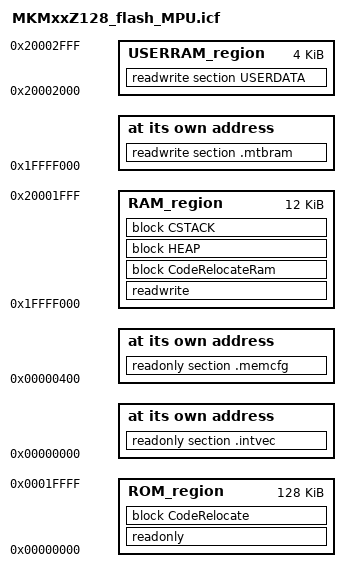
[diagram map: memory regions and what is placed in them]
/*###ICF### Section handled by ICF editor, don't touch! ****/
/*-Editor annotation file-*/
/* IcfEditorFile="$TOOLKIT_DIR$\config\ide\IcfEditor\cortex_v1_0.xml" */
/*-Specials-*/
define symbol __ICFEDIT_intvec_start__     = 0x00000000;
/*-Memory Regions-*/
define symbol __ICFEDIT_region_ROM_start__ = 0x00000000;
define symbol __ICFEDIT_region_ROM_end__   = 0x0001ffff;
define symbol __ICFEDIT_region_RAM_start__ = 0x1ffff000;
define symbol __ICFEDIT_region_RAM_end__   = 0x20001fff;
define symbol __ICFEDIT_region_USERRAM_start__ = 0x20002000;
define symbol __ICFEDIT_region_USERRAM_end__   = 0x20002fff;
/*-Sizes-*/
define symbol __ICFEDIT_size_cstack__ = 0x400;
define symbol __ICFEDIT_size_heap__   = 0x800;
/**** End of ICF editor section. ###ICF###*/

define symbol __memcfg_start__        = 0x00000400;
define symbol __mtbram_start__        = 0x1ffff000;

/* Export of symbol */
export symbol __ICFEDIT_region_ROM_start__;
export symbol __ICFEDIT_region_ROM_end__;
export symbol __ICFEDIT_region_RAM_start__;
export symbol __ICFEDIT_region_RAM_end__;
export symbol __ICFEDIT_region_USERRAM_start__;
export symbol __ICFEDIT_region_USERRAM_end__;

define memory mem with size = 4G;
define region ROM_region = mem:[from __ICFEDIT_region_ROM_start__ to __ICFEDIT_region_ROM_end__];
define region RAM_region = mem:[from __ICFEDIT_region_RAM_start__ to __ICFEDIT_region_RAM_end__];
define region USERRAM_region = mem:[from __ICFEDIT_region_USERRAM_start__ to __ICFEDIT_region_USERRAM_end__];

define block CSTACK    with alignment = 8, size = __ICFEDIT_size_cstack__   { };
define block HEAP      with alignment = 8, size = __ICFEDIT_size_heap__     { };

initialize manually { readwrite };
initialize manually { section .data};
initialize manually { section .textrw };
initialize manually { section USERDATA };
do not initialize   { zeroinit };

define block CodeRelocate { section .textrw_init };
define block CodeRelocateRam { section .textrw };

place at address mem:__ICFEDIT_intvec_start__ { readonly  section .intvec };
place at address mem:__memcfg_start__         { readonly  section .memcfg };
place at address mem:__mtbram_start__         { readwrite section .mtbram };

place in ROM_region   { readonly , block CodeRelocate };
place in RAM_region   { readwrite, block CodeRelocateRam, block HEAP, block CSTACK };
place in USERRAM_region   { readwrite section USERDATA };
